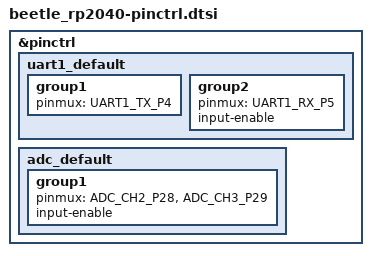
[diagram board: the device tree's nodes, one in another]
/*
 * Copyright (c) 2025 Jonas Berg
 *
 * SPDX-License-Identifier: Apache-2.0
 */

#include <dt-bindings/pinctrl/rpi-pico-rp2040-pinctrl.h>

&pinctrl {
	uart1_default: uart1_default {
		group1 {
			pinmux = <UART1_TX_P4>;
		};

		group2 {
			pinmux = <UART1_RX_P5>;
			input-enable;
		};
	};

	adc_default: adc_default {
		group1 {
			pinmux = <ADC_CH2_P28>, <ADC_CH3_P29>;
			input-enable;
		};
	};
};
